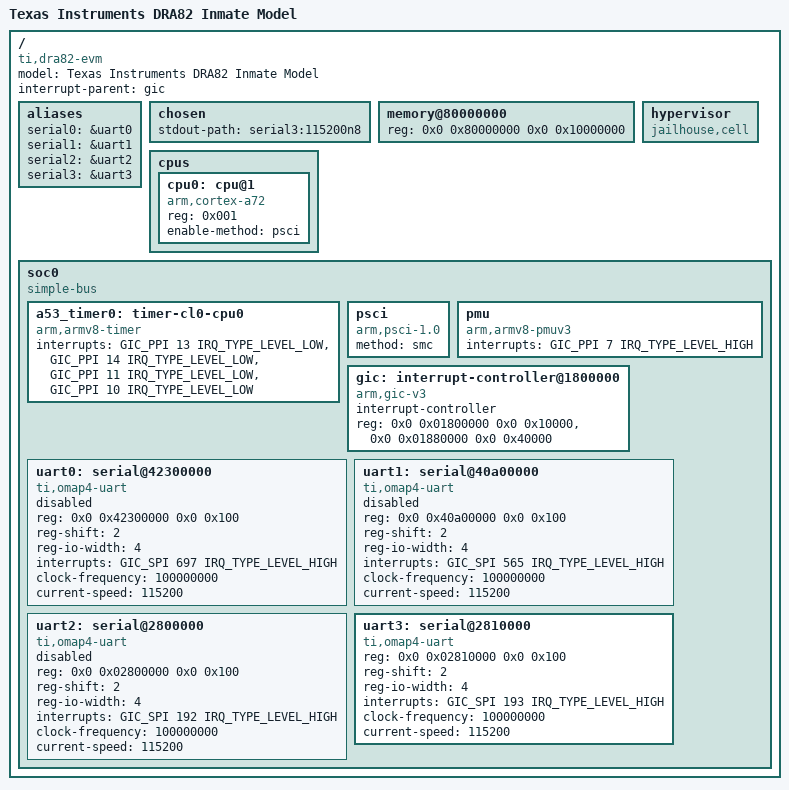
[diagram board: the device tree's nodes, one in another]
/dts-v1/;

#include <dt-bindings/interrupt-controller/irq.h>
#include <dt-bindings/interrupt-controller/arm-gic.h>

/ {
	model = "Texas Instruments DRA82 Inmate Model";
	compatible = "ti,dra82-evm", "ti,dra82";
	interrupt-parent = <&gic>;
	#address-cells = <2>;
	#size-cells = <2>;

	aliases {
		serial0 = &uart0;
		serial1 = &uart1;
		serial2 = &uart2;
		serial3 = &uart3;
	};

	chosen {
		stdout-path = "serial3:115200n8";
	};

	memory@80000000 {
		device_type = "memory";
		reg = <0x0 0x80000000 0x0 0x10000000>;
	};

	hypervisor {
		compatible = "jailhouse,cell";
	};

	cpus: cpus {
		#address-cells = <1>;
		#size-cells = <0>;

		cpu0: cpu@1 {
			compatible = "arm,cortex-a72","arm,armv8";
			reg = <0x001>;
			device_type = "cpu";
			enable-method = "psci";
		};
	};

	soc0: soc0 {
		compatible = "simple-bus";
		#address-cells = <2>;
		#size-cells = <2>;
		ranges;

		a53_timer0: timer-cl0-cpu0 {
			compatible = "arm,armv8-timer";
			interrupts = <GIC_PPI 13 IRQ_TYPE_LEVEL_LOW>, /* cntpsirq */
				     <GIC_PPI 14 IRQ_TYPE_LEVEL_LOW>, /* cntpnsirq */
				     <GIC_PPI 11 IRQ_TYPE_LEVEL_LOW>, /* cntvirq */
				     <GIC_PPI 10 IRQ_TYPE_LEVEL_LOW>; /* cnthpirq */
		};

		psci: psci {
			compatible = "arm,psci-1.0";
			method = "smc";
		};

		pmu: pmu {
			compatible = "arm,armv8-pmuv3";
			/* Recommendation from GIC500 TRM Table A.3 */
			interrupts = <GIC_PPI 7 IRQ_TYPE_LEVEL_HIGH>;
		};

		gic: interrupt-controller@1800000 {
			compatible = "arm,gic-v3";
			#address-cells = <2>;
			#size-cells = <2>;
			ranges;
			#interrupt-cells = <3>;
			interrupt-controller;
			/*
			 * NOTE: we are NOT gicv2 backward compat, so no GICC,
			 * GICH or GICV
			 */
			reg = <0x0 0x01800000 0x0 0x10000>,	/* GICD */
			      <0x0 0x01880000 0x0 0x40000>;	/* GICR */
		};

		uart0: serial@42300000 {
			/* USART0 in WKUP domain */
			compatible = "ti,omap4-uart", "ns16550a";
			reg = <0x0 0x42300000 0x0 0x100>;
			reg-shift = <2>;
			reg-io-width = <4>;
			interrupts = <GIC_SPI 697 IRQ_TYPE_LEVEL_HIGH>;
			clock-frequency = <100000000>;
			current-speed = <115200>;
			status = "disabled";
		};

		uart1: serial@40a00000 {
			/* USART0 in MCU domain */
			compatible = "ti,omap4-uart", "ns16550a";
			reg = <0x0 0x40a00000 0x0 0x100>;
			reg-shift = <2>;
			reg-io-width = <4>;
			interrupts = <GIC_SPI 565 IRQ_TYPE_LEVEL_HIGH>;
			clock-frequency = <100000000>;
			current-speed = <115200>;
			status = "disabled";
		};

		uart2: serial@2800000 {
			/* USART0 in MAIN domain */
			compatible = "ti,omap4-uart", "ns16550a";
			reg = <0x0 0x02800000 0x0 0x100>;
			reg-shift = <2>;
			reg-io-width = <4>;
			interrupts = <GIC_SPI 192 IRQ_TYPE_LEVEL_HIGH>;
			clock-frequency = <100000000>;
			current-speed = <115200>;
			status = "disabled";
		};

		uart3: serial@2810000 {
			/* USART1 in MAIN domain */
			compatible = "ti,omap4-uart", "ns16550a";
			reg = <0x0 0x02810000 0x0 0x100>;
			reg-shift = <2>;
			reg-io-width = <4>;
			interrupts = <GIC_SPI 193 IRQ_TYPE_LEVEL_HIGH>;
			clock-frequency = <100000000>;
			current-speed = <115200>;
		};

	};
};
